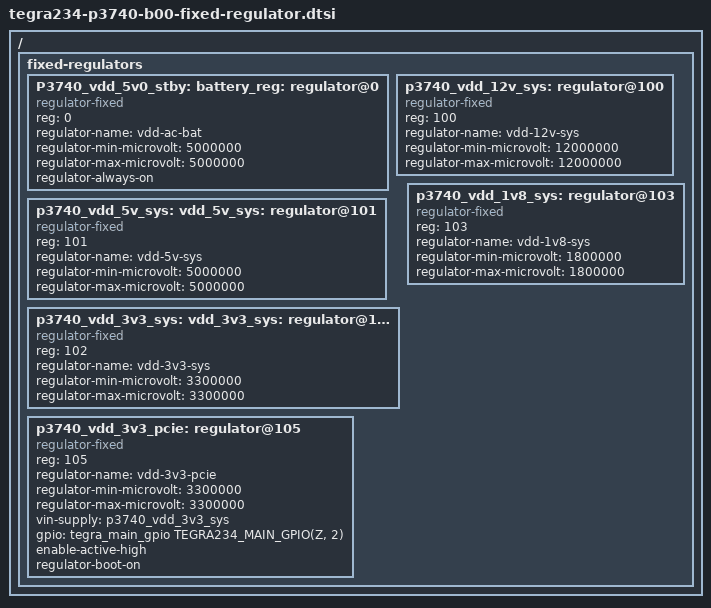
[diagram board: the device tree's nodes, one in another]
/*
 * Copyright (c) 2022, NVIDIA CORPORATION.  All rights reserved.
 *
 * This program is free software; you can redistribute it and/or modify
 * it under the terms of the GNU General Public License as published by
 * the Free Software Foundation; either version 2 of the License, or
 * (at your option) any later version.
 *
 * This program is distributed in the hope that it will be useful, but WITHOUT
 * ANY WARRANTY; without even the implied warranty of MERCHANTABILITY or
 * FITNESS FOR A PARTICULAR PURPOSE.  See the GNU General Public License for
 * more details.
 */

#include <dt-bindings/gpio/tegra234-gpio.h>
/ {
	fixed-regulators {
		P3740_vdd_5v0_stby: battery_reg: regulator@0 {
			compatible = "regulator-fixed";
			reg = <0>;
			regulator-name = "vdd-ac-bat";
			regulator-min-microvolt = <5000000>;
			regulator-max-microvolt = <5000000>;
			regulator-always-on;
		};
		p3740_vdd_12v_sys: regulator@100 {
			compatible = "regulator-fixed";
			reg = <100>;
			regulator-name = "vdd-12v-sys";
			regulator-min-microvolt = <12000000>;
			regulator-max-microvolt = <12000000>;
		};
		p3740_vdd_5v_sys: vdd_5v_sys: regulator@101 {
			compatible = "regulator-fixed";
			reg = <101>;
			regulator-name = "vdd-5v-sys";
			regulator-min-microvolt = <5000000>;
			regulator-max-microvolt = <5000000>;
		};
		p3740_vdd_3v3_sys: vdd_3v3_sys: regulator@102 {
			compatible = "regulator-fixed";
			reg = <102>;
			regulator-name = "vdd-3v3-sys";
			regulator-min-microvolt = <3300000>;
			regulator-max-microvolt = <3300000>;
		};
		p3740_vdd_1v8_sys: regulator@103 {
			compatible = "regulator-fixed";
			reg = <103>;
			regulator-name = "vdd-1v8-sys";
			regulator-min-microvolt = <1800000>;
			regulator-max-microvolt = <1800000>;
		};
		p3740_vdd_3v3_pcie: regulator@105 {
			compatible = "regulator-fixed";
			reg = <105>;
			regulator-name = "vdd-3v3-pcie";
			regulator-min-microvolt = <3300000>;
			regulator-max-microvolt = <3300000>;
			vin-supply = <&p3740_vdd_3v3_sys>;
			gpio = <&tegra_main_gpio TEGRA234_MAIN_GPIO(Z, 2) 0>;
			enable-active-high;
			regulator-boot-on;
		};
	};
};
